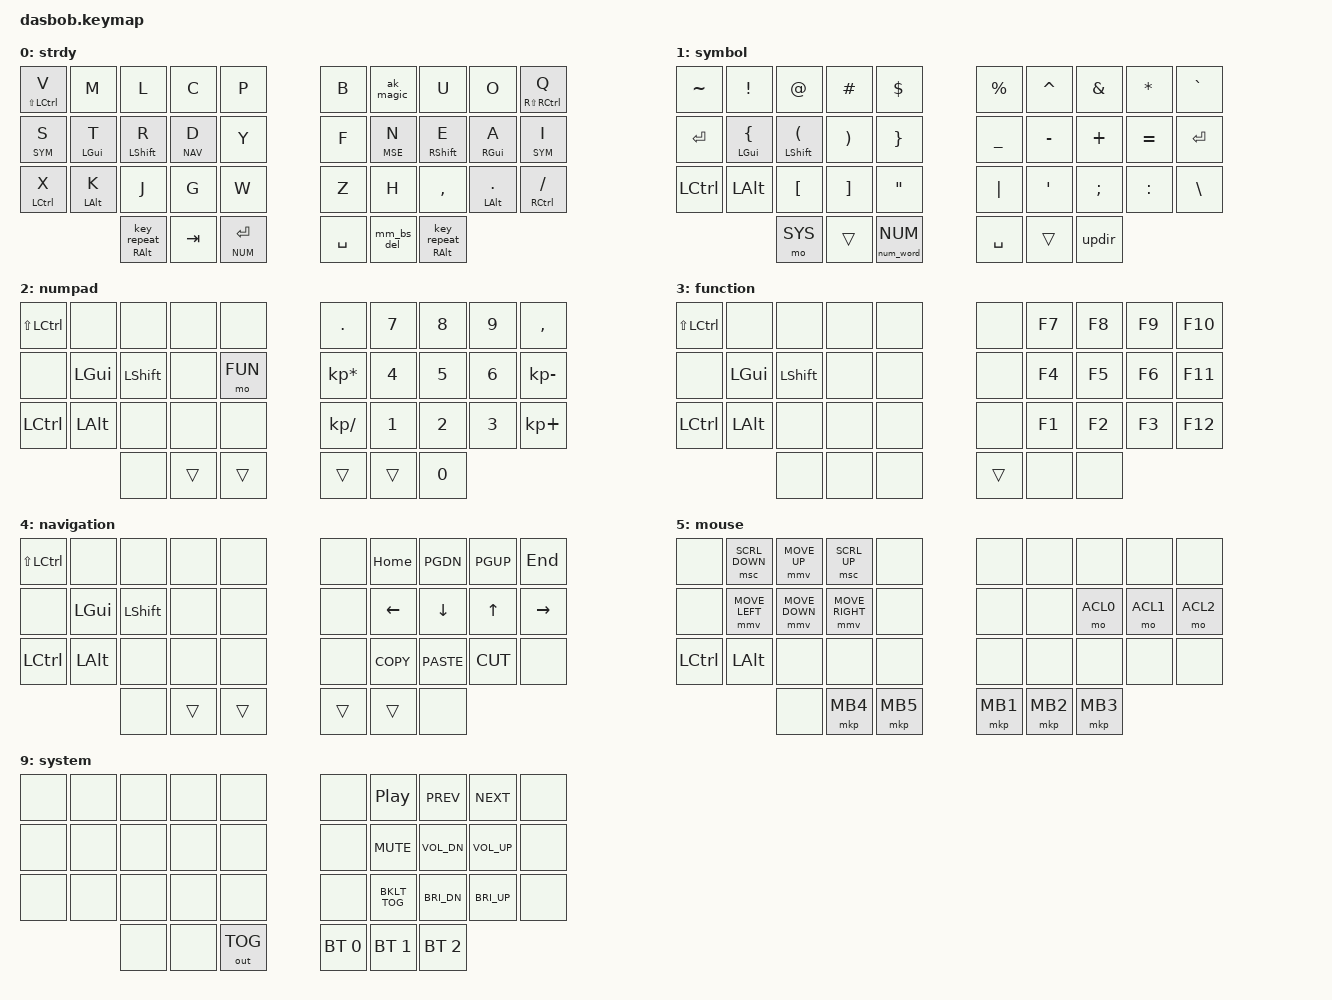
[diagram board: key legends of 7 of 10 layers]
#include <behaviors.dtsi>
#include <dt-bindings/zmk/keys.h>

#include <dt-bindings/zmk/bt.h>
#include <dt-bindings/zmk/outputs.h>

// put before pointing.h include
#define ZMK_POINTING_DEFAULT_MOVE_VAL 1000  // default: 600
#define ZMK_POINTING_DEFAULT_SCRL_VAL 15    // default: 10
#include <dt-bindings/zmk/pointing.h>
#include <input/processors.dtsi>

// provided by urob/zmk-auto-layer
// see https://github.com/urob/zmk-config?tab=readme-ov-file#numword for details
#include <behaviors/num_word.dtsi>

// layer shortcuts
#define BSE 0
#define SYM 1
#define NUM 2
#define FUN 3
#define NAV 4
#define MSE 5
#define ACL0 6
#define ACL1 7
#define ACL2 8
#define SYS 9

// full-transparent phandle-array for ACL layers
#define T_36 &trans &trans &trans &trans &trans    &trans &trans &trans &trans &trans \
             &trans &trans &trans &trans &trans    &trans &trans &trans &trans &trans \
             &trans &trans &trans &trans &trans    &trans &trans &trans &trans &trans \
                           &trans &trans &trans    &trans &trans &trans

#define REP_ALT &rp_ht RALT 0

// override the default flavor for Mod-Tap to what Layer-Tap is using
&mt {
    flavor = "tap-preferred";
};

// disable acceleration and set default speed for mouse movement and scrolling
&mmv {
    time-to-max-speed-ms = <0>;
};

&msc {
    time-to-max-speed-ms = <0>;
};

&mmv_input_listener {
    slow {
        layers = <ACL0>;
        input-processors = <&zip_xy_scaler 1 2>;
    };

    precision {
        layers = <ACL1>;
        input-processors = <&zip_xy_scaler 1 6>;
    };

    fast {
        layers = <ACL2>;
        input-processors = <&zip_xy_scaler 3 1>;
    };
};

/ {
    behaviors {
        // Smart Backspace: Tap=BSPC, Shift+Tap=DEL
        mm_bs_del: mm_bs_del {
            compatible = "zmk,behavior-mod-morph";
            #binding-cells = <0>;
            bindings = <&kp BSPC>, <&kp DEL>;
            mods = <(MOD_LSFT|MOD_RSFT)>;
        };

        // Smart Repeat: Tap=Repeat, Hold=AltGr
        // NOTE: hold-tap enforces 2 arguments, so just pass anything (e.g. 0), it will be ignored in the binding
        rp_ht: repeat_hold_tap {
            compatible = "zmk,behavior-hold-tap";
            #binding-cells = <2>;
            flavor = "tap-preferred";
            require-prior-idle-ms = <150>;
            tapping-term-ms = <280>;
            quick-tap-ms = <175>;
            bindings = <&kp>, <&key_repeat>;
            hold-trigger-on-release;
        };

        // "Magic Key", using https://github.com/urob/zmk-adaptive-key/
        ak_magic: ak_magic {
            compatible = "zmk,behavior-adaptive-key";
            #binding-cells = <0>;
            bindings = <&kp K>;

            // cmdline
            akt_ls   { trigger-keys = <L>; max-prior-idle-ms = <300>; bindings = <&kp S &kp SPACE>; };
            akt_cd   { trigger-keys = <C>; max-prior-idle-ms = <300>; bindings = <&kp D &kp SPACE>; };
            akt_rm   { trigger-keys = <R>; max-prior-idle-ms = <300>; bindings = <&kp M &kp SPACE>; };
            akt_mv   { trigger-keys = <M>; max-prior-idle-ms = <300>; bindings = <&kp V &kp SPACE>; };
            akt_git  { trigger-keys = <G>; max-prior-idle-ms = <300>; bindings = <&kp I &kp T &kp SPACE>; };
            akt_vim  { trigger-keys = <V>; max-prior-idle-ms = <300>; bindings = <&kp I &kp M &kp SPACE>; };
            akt_yadm { trigger-keys = <Y>; max-prior-idle-ms = <300>; bindings = <&kp A &kp D &kp M &kp SPACE>; };

            // words + endings
            akt_the { trigger-keys = <T>; max-prior-idle-ms = <300>; bindings = <&kp H &kp E &kp SPACE>; };
            akt_and { trigger-keys = <A>; max-prior-idle-ms = <300>; bindings = <&kp N &kp D &kp SPACE>; };
            akt_ing { trigger-keys = <I>; max-prior-idle-ms = <300>; bindings = <&kp N &kp G &kp SPACE>; };
        };

        // "Arcane Key", cmp: https://www.reddit.com/r/KeyboardLayouts/comments/1cb2v3l
        rep_l: rep_l {
            compatible = "zmk,behavior-adaptive-key";
            #binding-cells = <0>;
            bindings = <&key_repeat>; // DEFAULT: last key was on right
            // same_side_trigger { trigger-keys = <ALPHAS_L>; max-prior-idle-ms = <300>; bindings = <&kp L>; }
        };

        rep_r: rep_r {
            compatible = "zmk,behavior-adaptive-key";
            #binding-cells = <0>;
            bindings = <&key_repeat>; // DEFAULT: last key was on left
            // same_side_trigger { trigger-keys = <ALPHAS_R>; max-prior-idle-ms = <300>; bindings = <&kp L>; }
        };
    };

    combos {
        compatible = "zmk,combos";

        // Escape
        combo_esc_left  { timeout-ms = <50>; key-positions = <12 14>; bindings = <&kp ESC>; };
        combo_esc_right { timeout-ms = <50>; key-positions = <15 17>; bindings = <&kp ESC>; };

        // Caps Word
        combo_caps_word { timeout-ms = <50>; key-positions = <11 18>; bindings = <&caps_word>; };

        // Symbols Left
        combo_sym_tild { timeout-ms = <50>; key-positions = <0 10>; bindings = <&kp TILDE>; };
        combo_sym_exlm { timeout-ms = <50>; key-positions = <1 11>; bindings = <&kp EXCL>; };
        combo_sym_at   { timeout-ms = <50>; key-positions = <2 12>; bindings = <&kp AT>; };
        combo_sym_hash { timeout-ms = <50>; key-positions = <3 13>; bindings = <&kp HASH>; };
        combo_sym_dlr  { timeout-ms = <50>; key-positions = <4 14>; bindings = <&kp DOLLAR>; };

        combo_sym_perc { timeout-ms = <50>; key-positions = <10 20>; bindings = <&kp PRCNT>; };
        combo_sym_circ { timeout-ms = <50>; key-positions = <11 21>; bindings = <&kp CARET>; };
        combo_sym_ampr { timeout-ms = <50>; key-positions = <12 22>; bindings = <&kp AMPS>; };
        combo_sym_astr { timeout-ms = <50>; key-positions = <13 23>; bindings = <&kp ASTERISK>; };
        combo_sym_grv  { timeout-ms = <50>; key-positions = <14 24>; bindings = <&kp GRAVE>; };

        // Symbols Right
        combo_sym_unds { timeout-ms = <50>; key-positions = <5 15>; bindings = <&kp UNDER>; };
        combo_sym_mins { timeout-ms = <50>; key-positions = <6 16>; bindings = <&kp MINUS>; };
        combo_sym_plus { timeout-ms = <50>; key-positions = <7 17>; bindings = <&kp PLUS>; };
        combo_sym_eql  { timeout-ms = <50>; key-positions = <8 18>; bindings = <&kp EQUAL>; };

        combo_sym_pipe { timeout-ms = <50>; key-positions = <15 25>; bindings = <&kp PIPE>; };
        combo_sym_quot { timeout-ms = <50>; key-positions = <16 26>; bindings = <&kp SQT>; };
        combo_sym_scln { timeout-ms = <50>; key-positions = <17 27>; bindings = <&kp SEMI>; };
        combo_sym_coln { timeout-ms = <50>; key-positions = <18 28>; bindings = <&kp COLON>; };
        combo_sym_bsls { timeout-ms = <50>; key-positions = <19 29>; bindings = <&kp BSLH>; };
    };

    macros {
        ZMK_MACRO(updir, wait-ms = <30>; tap-ms = <40>; bindings = <&kp DOT &kp DOT &kp SLASH>;)
    };

    keymap {
        compatible = "zmk,keymap";

        /*
        * ┌───┬───┬───┬───┬───┐       ┌───┬───┬───┬───┬───┐
        * │ V │ M │ L │ C │ P │       │ B │ ★ │ U │ O │ Q │
        * ├───┼───┼───┼───┼───┤       ├───┼───┼───┼───┼───┤
        * │ S │ T │ R │ D │ Y │       │ F │ N │ E │ A │ I │
        * ├───┼───┼───┼───┼───┤       ├───┼───┼───┼───┼───┤
        * │ X │ K │ J │ G │ W │       │ Z │ H │ , │ . │ / │
        * └───┴───┴───┴───┴───┘       └───┴───┴───┴───┴───┘
        *           ┌───┐                   ┌───┐
        *           │REP├───┐           ┌───┤REP│
        *           └───┤TAB├───┐   ┌───┤BSP├───┘
        *               └───┤SPC│   │SPC├───┘
        *                   └───┘   └───┘
        */

        strdy {
            bindings = <
                &mt LS(LCTRL) V &kp M      &kp L        &kp C     &kp P       &kp B &ak_magic &kp U        &kp O        &mt RS(RCTRL) Q
                &lt SYM S       &mt LGUI T &mt LSHIFT R &lt NAV D &kp Y       &kp F &lt MSE N &mt RSHIFT E &mt RGUI A   &lt SYM I
                &mt LCTRL X     &mt LALT K &kp J        &kp G     &kp W       &kp Z &kp H     &kp COMMA    &mt LALT DOT &mt RCTRL SLASH

                                        REP_ALT &kp TAB   &lt NUM ENTER       &kp SPACE &mm_bs_del  REP_ALT
            >;
        };

        symbol {
            bindings = <
                &kp TILDE &kp EXCL       &kp AT          &kp HASH &kp DOLLAR          &kp PERCENT  &kp CARET     &kp AMPS     &kp ASTERISK     &kp GRAVE
                &kp ENTER &mt LGUI LBRC  &mt LSHIFT LPAR &kp RPAR &kp RBRC            &kp UNDER    &kp MINUS     &kp PLUS     &kp EQUAL        &kp ENTER
                &kp LCTRL &kp LALT       &kp LBKT        &kp RBKT &kp DQT             &kp PIPE     &kp SQT       &kp SEMI     &kp COLON        &kp BSLH

                               &mo SYS &trans   &num_word NUM      &kp SPACE &trans &updir
            >;
        };

        numpad {
            bindings = <
                &kp LS(LCTRL) &none     &none       &none     &none          &kp DOT          &kp N7    &kp N8    &kp N9    &kp COMMA
                &none         &kp LGUI  &kp LSHIFT  &none     &mo FUN        &kp KP_MULTIPLY  &kp N4    &kp N5    &kp N6    &kp KP_MINUS
                &kp LCTRL     &kp LALT  &none       &none     &none          &kp KP_SLASH     &kp N1    &kp N2    &kp N3    &kp KP_PLUS

                               &none &trans   &trans     &trans &trans  &kp N0
            >;
        };

        function {
            bindings = <
                &kp LS(LCTRL) &none     &none       &none     &none          &none  &kp F7    &kp F8    &kp F9    &kp F10
                &none         &kp LGUI  &kp LSHIFT  &none     &none          &none  &kp F4    &kp F5    &kp F6    &kp F11
                &kp LCTRL     &kp LALT  &none       &none     &none          &none  &kp F1    &kp F2    &kp F3    &kp F12

                               &none &none &none      &trans &none  &none
            >;
        };

        navigation {
            bindings = <
                &kp LS(LCTRL) &none     &none       &none     &none          &none  &kp HOME   &kp PGDN    &kp PGUP  &kp END
                &none         &kp LGUI  &kp LSHIFT  &none     &none          &none  &kp LEFT   &kp DOWN    &kp UP    &kp RIGHT
                &kp LCTRL     &kp LALT  &none       &none     &none          &none  &kp K_COPY &kp K_PASTE &kp K_CUT &none

                               &none &trans &trans      &trans &trans  &none
            >;
        };

        mouse {
            bindings = <
                &none     &msc SCRL_DOWN &mmv MOVE_UP   &msc SCRL_UP    &none          &none  &none    &none    &none    &none
                &none     &mmv MOVE_LEFT &mmv MOVE_DOWN &mmv MOVE_RIGHT &none          &none  &none    &mo ACL0 &mo ACL1 &mo ACL2
                &kp LCTRL &kp LALT       &none          &none           &none          &none  &none    &none    &none    &none

                               &none  &mkp MB4  &mkp MB5      &mkp MB1 &mkp MB2 &mkp MB3
            >;
        };

        // Speed Layers for Input Processors
        mouse_acl0 { bindings = < T_36 >; };
        mouse_acl1 { bindings = < T_36 >; };
        mouse_acl2 { bindings = < T_36 >; };

        system {
            bindings = <
                &none      &none    &none     &none     &none          &none  &kp C_PLAY_PAUSE &kp C_PREV   &kp C_NEXT   &none
                &none      &none    &none     &none     &none          &none  &kp C_MUTE       &kp C_VOL_DN &kp C_VOL_UP &none
                &none      &none    &none     &none     &none          &none  &kp C_BKLT_TOG   &kp C_BRI_DN &kp C_BRI_UP &none

                                     &none &none &out OUT_TOG          &bt BT_SEL 0 &bt BT_SEL 1 &bt BT_SEL 2
            >;
        };
    };
 };
